# SN32F420 register map
Vendor: SONiX Technology Co., Ltd.; Series: SN32F420; File version: 1.00
CPU: CM0 r0p0, little endian, no MPU, no FPU, 2 interrupt priority bits
Registers are 32-bit, read-write, reset 0x0 unless marked. A register's access mark holds for its fields unless they carry their own. Offsets are from the block's base; [hi:lo] are bit positions.

## SN_GPIO2 — General Purpose I/O
Base 0x40048000
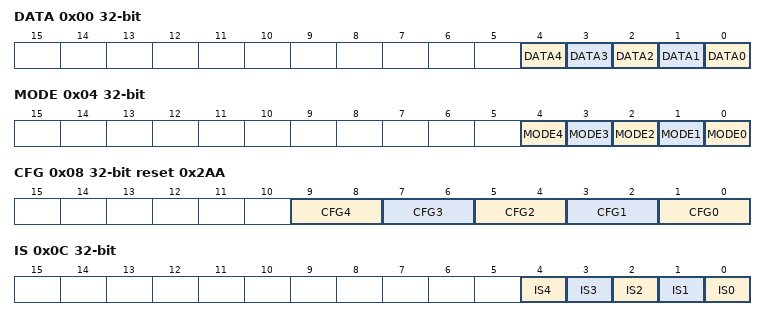
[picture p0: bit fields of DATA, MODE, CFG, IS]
0x00 DATA — Offset:0x00 GPIO Port n Data register
  [4] DATA4 — Data of Pn.4
    0=Low (Pn.4 is 0); 1=High (Pn.4 is 1)
  [3] DATA3 — Data of Pn.3
    0=Low (Pn.3 is 0); 1=High (Pn.3 is 1)
  [2] DATA2 — Data of Pn.2
    0=Low (Pn.2 is 0); 1=High (Pn.2 is 1)
  [1] DATA1 — Data of Pn.1
    0=Low (Pn.1 is 0); 1=High (Pn.1 is 1)
  [0] DATA0 — Data of Pn.0
    0=Low (Pn.0 is 0); 1=High (Pn.0 is 1)
0x04 MODE — Offset:0x04 GPIO Port n Mode register
  [4] MODE4 — Mode of Pn.4
    0=I (Pn.4 is Input pin); 1=O (Pn.4 is Output pin)
  [3] MODE3 — Mode of Pn.3
    0=I (Pn.3 is Input pin); 1=O (Pn.3 is Output pin)
  [2] MODE2 — Mode of Pn.2
    0=I (Pn.2 is Input pin); 1=O (Pn.2 is Output pin)
  [1] MODE1 — Mode of Pn.1
    0=I (Pn.1 is Input pin); 1=O (Pn.1 is Output pin)
  [0] MODE0 — Mode of Pn.0
    0=I (Pn.0 is Input pin); 1=O (Pn.0 is Output pin)
0x08 CFG reset 0x2AA — Offset:0x08 GPIO Port n Configuration register
  [all] fields
    0=00b (Reserved); 1=01b (Reserved); 2=10b (Inactive (schmitt trigger enabled)); 3=11b (Inactive (schmitt trigger disabled))
  [9:8] CFG4 — Configuration of Pn.4
  [7:6] CFG3 — Configuration of Pn.3
  [5:4] CFG2 — Configuration of Pn.2
  [3:2] CFG1 — Configuration of Pn.1
  [1:0] CFG0 — Configuration of Pn.0
0x0C IS — Offset:0x0C GPIO Port n Interrupt Sense register
  [4] IS4 — Interrupt on Pn.4 is event or edge sensitive
    0=Edge (Interrupt on Pn.4 is edge sensitive); 1=Event (Interrupt on Pn.4 is event sensitive)
  [3] IS3 — Interrupt on Pn.3 is event or edge sensitive
    0=Edge (Interrupt on Pn.3 is edge sensitive); 1=Event (Interrupt on Pn.3 is event sensitive)
  [2] IS2 — Interrupt on Pn.2 is event or edge sensitive
    0=Edge (Interrupt on Pn.2 is edge sensitive); 1=Event (Interrupt on Pn.2 is event sensitive)
  [1] IS1 — Interrupt on Pn.1 is event or edge sensitive
    0=Edge (Interrupt on Pn.1 is edge sensitive); 1=Event (Interrupt on Pn.1 is event sensitive)
  [0] IS0 — Interrupt on Pn.0 is event or edge sensitive
    0=Edge (Interrupt on Pn.0 is edge sensitive); 1=Event (Interrupt on Pn.0 is event sensitive)
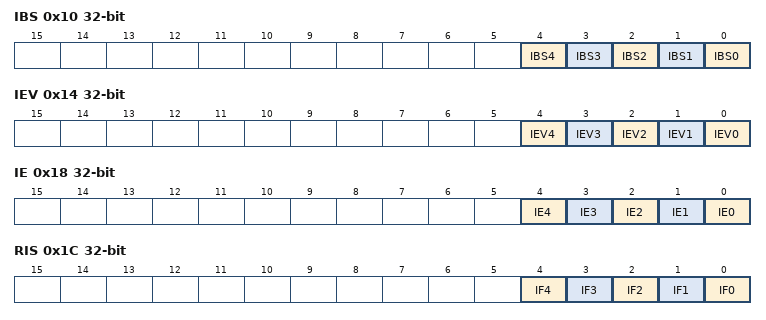
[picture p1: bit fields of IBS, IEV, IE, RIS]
0x10 IBS — Offset:0x10 GPIO Port n Interrupt Both-edge Sense register
  [4] IBS4 — Interrupt on Pn.4 is triggered ob both edges
    0=IEV (Interrupt on Pn.4 is controlled by GPIOn_IEV register); 1=Both edges on Pn.4 trigger an interrupt
  [3] IBS3 — Interrupt on Pn.3 is triggered ob both edges
    0=IEV (Interrupt on Pn.3 is controlled by GPIOn_IEV register); 1=Both edges on Pn.3 trigger an interrupt
  [2] IBS2 — Interrupt on Pn.2 is triggered ob both edges
    0=IEV (Interrupt on Pn.2 is controlled by GPIOn_IEV register); 1=Both edges on Pn.2 trigger an interrupt
  [1] IBS1 — Interrupt on Pn.1 is triggered ob both edges
    0=IEV (Interrupt on Pn.1 is controlled by GPIOn_IEV register); 1=Both edges on Pn.1 trigger an interrupt
  [0] IBS0 — Interrupt on Pn.0 is triggered ob both edges
    0=IEV (Interrupt on Pn.0 is controlled by GPIOn_IEV register); 1=Both edges on Pn.0 trigger an interrupt
0x14 IEV — Offset:0x14 GPIO Port n Interrupt Event register
  [4] IEV4 — Interrupt trigged event on Pn.4
    0=Rising/High (Rising edge or High level on Pn.4 triggers an interrupt); 1=Falling/Low (Falling edge or Low level on Pn.4 triggers an interrupt)
  [3] IEV3 — Interrupt trigged event on Pn.3
    0=Rising/High (Rising edge or High level on Pn.3 triggers an interrupt); 1=Falling/Low (Falling edge or Low level on Pn.3 triggers an interrupt)
  [2] IEV2 — Interrupt trigged event on Pn.2
    0=Rising/High (Rising edge or High level on Pn.2 triggers an interrupt); 1=Falling/Low (Falling edge or Low level on Pn.2 triggers an interrupt)
  [1] IEV1 — Interrupt trigged event on Pn.1
    0=Rising/High (Rising edge or High level on Pn.1 triggers an interrupt); 1=Falling/Low (Falling edge or Low level on Pn.1 triggers an interrupt)
  [0] IEV0 — Interrupt trigged event on Pn.0
    0=Rising/High (Rising edge or High level on Pn.0 triggers an interrupt); 1=Falling/Low (Falling edge or Low level on Pn.0 triggers an interrupt)
0x18 IE — Offset:0x18 GPIO Port n Interrupt Enable register
  [4] IE4 — Interrupt on Pn.4 enable
    0=Disable interrupt on Pn.4; 1=Enable interrupt on Pn.4
  [3] IE3 — Interrupt on Pn.3 enable
    0=Disable interrupt on Pn.3; 1=Enable interrupt on Pn.3
  [2] IE2 — Interrupt on Pn.2 enable
    0=Disable interrupt on Pn.2; 1=Enable interrupt on Pn.2
  [1] IE1 — Interrupt on Pn.1 enable
    0=Disable interrupt on Pn.1; 1=Enable interrupt on Pn.1
  [0] IE0 — Interrupt on Pn.0 enable
    0=Disable interrupt on Pn.0; 1=Enable interrupt on Pn.0
0x1C RIS ro — Offset:0x1C GPIO Port n Raw Interrupt Status register
  [4] IF4 — Pn.4 raw interrupt flag
    0=None (No interrupt on Pn.4); 1=Met interrupt requirements (Interrupt requirements met on Pn.4)
  [3] IF3 — Pn.3 raw interrupt flag
    0=None (No interrupt on Pn.3); 1=Met interrupt requirements (Interrupt requirements met on Pn.3)
  [2] IF2 — Pn.2 raw interrupt flag
    0=None (No interrupt on Pn.2); 1=Met interrupt requirements (Interrupt requirements met on Pn.2)
  [1] IF1 — Pn.1 raw interrupt flag
    0=None (No interrupt on Pn.1); 1=Met interrupt requirements (Interrupt requirements met on Pn.1)
  [0] IF0 — Pn.0 raw interrupt flag
    0=None (No interrupt on Pn.0); 1=Met interrupt requirements (Interrupt requirements met on Pn.0)
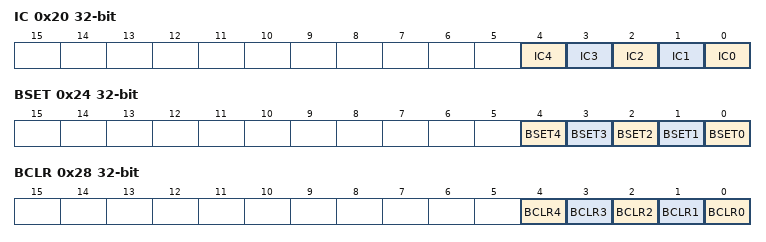
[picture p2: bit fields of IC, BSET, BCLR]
0x20 IC wo — Offset:0x20 GPIO Port n Interrupt Clear register
  [4] IC4 — Pn.4 interrupt flag clear
    0=None (No effect); 1=Clear interrupt flag on Pn.4
  [3] IC3 — Pn.3 interrupt flag clear
    0=None (No effect); 1=Clear interrupt flag on Pn.3
  [2] IC2 — Pn.2 interrupt flag clear
    0=None (No effect); 1=Clear interrupt flag on Pn.2
  [1] IC1 — Pn.1 interrupt flag clear
    0=None (No effect); 1=Clear interrupt flag on Pn.1
  [0] IC0 — Pn.0 interrupt flag clear
    0=None (No effect); 1=Clear interrupt flag on Pn.0
0x24 BSET wo — Offset:0x24 GPIO Port n Bits Set Operation register
  [4] BSET4 — Set Pn.4
    0=None (No effect); 1=Set (Set Pn.4 to 1)
  [3] BSET3 — Set Pn.3
    0=None (No effect); 1=Set (Set Pn.3 to 1)
  [2] BSET2 — Set Pn.2
    0=None (No effect); 1=Set (Set Pn.2 to 1)
  [1] BSET1 — Set Pn.1
    0=None (No effect); 1=Set (Set Pn.1 to 1)
  [0] BSET0 — Set Pn.0
    0=None (No effect); 1=Set (Set Pn.0 to 1)
0x28 BCLR wo — Offset:0x28 GPIO Port n Bits Clear Operation register
  [4] BCLR4 — Clear Pn.4
    0=None (No effect); 1=Clear Pn.4
  [3] BCLR3 — Clear Pn.3
    0=None (No effect); 1=Clear Pn.3
  [2] BCLR2 — Clear Pn.2
    0=None (No effect); 1=Clear Pn.2
  [1] BCLR1 — Clear Pn.1
    0=None (No effect); 1=Clear Pn.1
  [0] BCLR0 — Clear Pn.0
    0=None (No effect); 1=Clear Pn.0
